# DSS_EDP0_V2A_CORE_VP_REGS_APB register map
Vendor: Texas Instruments
Registers are 32-bit, access per field, reset 0x0 unless marked. A register's access mark holds for its fields unless they carry their own. Offsets are as the file gives them; [hi:lo] are bit positions; {n}, {i} and the like mark numbered series; 'fields as' and 'values as' point back to an identical list.

## DSS_EDP0_V2A_CORE_VP_REGS_APB (part 2 of 3)
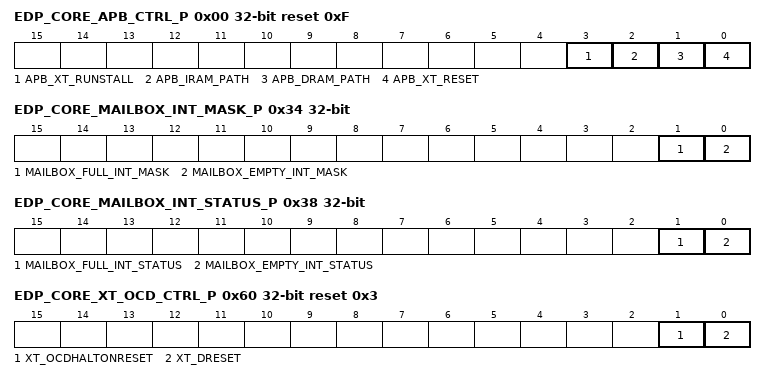
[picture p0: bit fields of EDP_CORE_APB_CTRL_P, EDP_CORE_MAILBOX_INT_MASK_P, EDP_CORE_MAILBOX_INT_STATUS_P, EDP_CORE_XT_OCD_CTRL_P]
0x00 EDP_CORE_APB_CTRL_P reset 0xF — APB main control register
  [3] APB_XT_RUNSTALL rw — When 1 stalls the CPU from executing further instructions.
  [2] APB_IRAM_PATH rw — Unused.
  [1] APB_DRAM_PATH rw — Unused.
  [0] APB_XT_RESET rw — Internal uCPU reset.
0x04 EDP_CORE_XT_INT_CTRL_P — Inernal CPU Interrupt Polarity Control Register.
  [1:0] XT_INT_POLARITY rw — Each bit inverts appropriate interrupt signal provided do internal CPU interrupt input.
0x08 EDP_CORE_MAILBOX_FULL_ADDR_P ro — Mailbox full indication status register. This register provides a status of the mailbox that is used to send messages from the Host processor to internal uCPU.Mailbox full flag can be a source of mailbox interrupt.
  [0] MAILBOX_FULL — Mailbox full indication.
0x0C EDP_CORE_MAILBOX_EMPTY_ADDR_P ro reset 0x1 — Mailbox empty indication status register. This register provides a status of the mailbox that is used to send responses from the internal uCPU to host processor as a result of previously sent message.Mailbox empty flag can be a source of not-empty mailbox interrupt.
  [0] MAILBOX_EMPTY — Mailbox empty indication.
0x10 EDP_CORE_MAILBOX0_WR_DATA_P — Mailbox write data register.
  [7:0] MAILBOX0_WR_DATA rw — Mailbox write data.
0x14 EDP_CORE_MAILBOX0_RD_DATA_P ro — Mailbox Read data register.
  [7:0] MAILBOX0_RD_DATA — Mailbox Read data.
0x18 EDP_CORE_KEEP_ALIVE_P ro — Software keep alive counter.
  [7:0] KEEP_ALIVE_CNT
0x1C EDP_CORE_VER_l_P ro — Software Version Register.
  [7:0] VER_LSB — Software Version lower byte.
0x20 EDP_CORE_VER_H_P ro — Software Version Register.
  [7:0] VER_MSB — Software Version higher byte.
0x24 EDP_CORE_VER_LIB_L_ADDR_P ro — Software Library Version Register.
  [7:0] SW_LIB_VER_L — Software Library Version lower byte.
0x28 EDP_CORE_VER_LIB_H_ADDR_P ro — Software Library Version Register.
  [7:0] SW_LIB_VER_H — Software Library Version higher byte.
0x2C EDP_CORE_SW_DEBUG_l_P ro — Software/Firmware Debug Register.
  [7:0] SW_DEBUG_7_0 — Register used for debug purposes [lower byte].
0x30 EDP_CORE_SW_DEBUG_H_P ro — Software/Firmware Debug Register.
  [7:0] SW_DEBUG_15_8 — Register used for debug purposes [higher byte].
0x34 EDP_CORE_MAILBOX_INT_MASK_P — Mailbox Interrupt mask register.
  [1] MAILBOX_FULL_INT_MASK rw — Mailbox Full Interrupt mask
  [0] MAILBOX_EMPTY_INT_MASK rw — Mailbox Not-empty Interrupt mask
0x38 EDP_CORE_MAILBOX_INT_STATUS_P ro — Mailbox Interrupt Status register.
  [1] MAILBOX_FULL_INT_STATUS — Mailbox full interrupt.
  [0] MAILBOX_EMPTY_INT_STATUS — Mailbox not-empty interrupt.
0x3C EDP_CORE_SW_CLK_l_P — Core Clock frequency
  [7:0] SW_CLOCK_VAL_L rw — Fractional of the clock decimal value.
0x40 EDP_CORE_SW_CLK_H_P reset 0x64 — Core Clock frequency
  [7:0] SW_CLOCK_VAL_H rw — Clock frequency in decimal values.
0x44 EDP_CORE_SW_EVENTS0_P ro — Bits [7:0] of the software events status vector. This register is used to report internal events that have been detected by the firmware to the host processor. Register is written by the internal uCPU. It is cleared upon read by the Host processor. Reported events can be source of interrupt reported in APB_INT_STATUS[1] register if this interrupt is enabled.Detailed description of the currently supported events can be found in HD Display TX Controller Programming Interface document.
  [7:0] SW_EVENTS7_0 — Each bit represents a separate event reported by the internal uCPU.
{0x44+4i} EDP_CORE_SW_EVENTS{i}_P ro (i=1..3) — SW Event {i} register
  [7:0] SW_EVENTS{8i+7}_{8i} — Each bit represents a separate event reported by the internal uCPU.
0x60 EDP_CORE_XT_OCD_CTRL_P reset 0x3 — Internal CPU - On Chip Debug (OCD) Ctrl Register
  [1] XT_OCDHALTONRESET rw — Internal CPU - Halt On Reget configuration register
  [0] XT_DRESET rw — Internal CPU - Dreset control register
0x64 EDP_CORE_XT_OCD_CTRL_RO_P ro — Internal CPU - OCD R0 mode configuration
  [0] XT_XOCDMODE — Internal CPU - OCD mode configuration
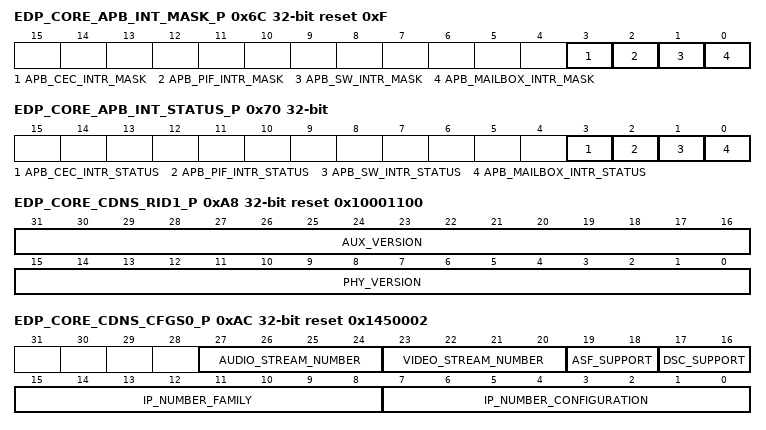
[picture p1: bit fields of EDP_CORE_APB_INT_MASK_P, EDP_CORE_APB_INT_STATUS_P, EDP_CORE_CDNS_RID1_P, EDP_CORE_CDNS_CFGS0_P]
0x6C EDP_CORE_APB_INT_MASK_P reset 0xF — APB Interrupt Mask Register
  [3] APB_CEC_INTR_MASK rw — Reserved field.
  [2] APB_PIF_INTR_MASK rw — PIF module Interrupt mask
  [1] APB_SW_INTR_MASK rw — SW Event Interrupt mask
  [0] APB_MAILBOX_INTR_MASK rw — Mailbox Interrupt mask
0x70 EDP_CORE_APB_INT_STATUS_P ro — APB interrupt status register
  [3] APB_CEC_INTR_STATUS — Reserved.
  [2] APB_PIF_INTR_STATUS — PIF module Interrupt status.
  [1] APB_SW_INTR_STATUS — SW Events Interrupt status.
  [0] APB_MAILBOX_INTR_STATUS — Mailbox Interrupt status.
0xA0 EDP_CORE_CDNS_DID_P ro reset 0x8546 — Number identifying the IP.Corresponds to IP Part Number.
  [31:0] IPVER — 0x8546 - DisplayPort 1.4/EmbeddedDisplayPort 1.4 Tx Combo Controller
0xA4 EDP_CORE_CDNS_RID0_P ro reset 0x2000 — Number identifying IP version.
  [15:0] IP_VERSION — IP version: r
0xA8 EDP_CORE_CDNS_RID1_P ro reset 0x10001100 — Numbers identifying PHY and AUX version
  [31:16] AUX_VERSION — AUX version: r
  [15:0] PHY_VERSION — PHY version: r
0xAC EDP_CORE_CDNS_CFGS0_P ro reset 0x1450002 — Numbers identifying the capabilities/configuration of the MHDP controller. Values not explicitely listed below ar ereserved for future use.
  [27:24] AUDIO_STREAM_NUMBER — Secondary configuration.
  [23:20] VIDEO_STREAM_NUMBER — Secondary configuration.
  [19:18] ASF_SUPPORT — Secondary configuration.
  [17:16] DSC_SUPPORT — Secondary configuration.
  [15:8] IP_NUMBER_FAMILY — Main configuration.
  [7:0] IP_NUMBER_CONFIGURATION — Main configuration.
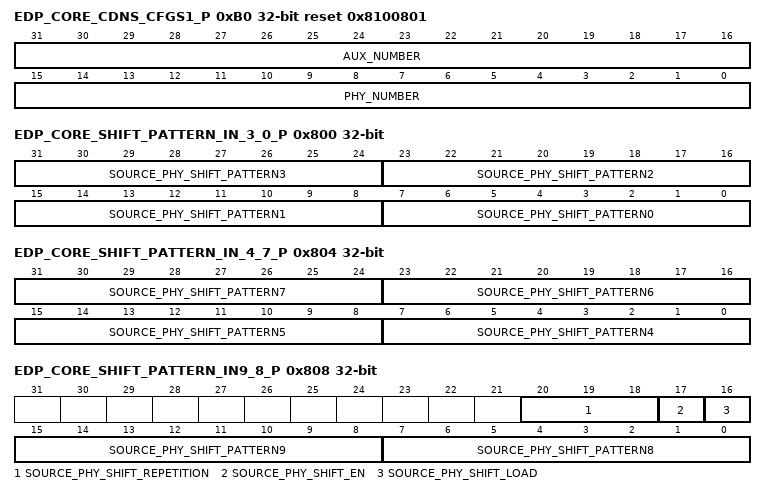
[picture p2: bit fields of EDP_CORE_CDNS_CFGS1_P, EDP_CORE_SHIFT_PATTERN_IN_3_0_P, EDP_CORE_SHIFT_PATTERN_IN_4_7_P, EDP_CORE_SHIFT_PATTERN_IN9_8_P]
0xB0 EDP_CORE_CDNS_CFGS1_P ro reset 0x8100801 — Numbers identifying type of PHY and AUX are integrated in the IPS. Fixed for a given IPS configuration.
  [31:16] AUX_NUMBER — AUX IP Number, according to versioning scheme.
  [15:0] PHY_NUMBER — PHY IP Number, according to versioning scheme.
0x800 EDP_CORE_SHIFT_PATTERN_IN_3_0_P rw — HDMI shift pattern 3-0
  [8n+7:8n] SOURCE_PHY_SHIFT_PATTERN{n} (n=0..3) — Input to hdmi_pattern_shift
0x804 EDP_CORE_SHIFT_PATTERN_IN_4_7_P rw — HDMI shift pattern 4-7
  [8n-25:8n-32] SOURCE_PHY_SHIFT_PATTERN{n} (n=4..7) — Input to hdmi_pattern_shift
0x808 EDP_CORE_SHIFT_PATTERN_IN9_8_P — HDMI shift pattern 9-8 with control bits
  [20:18] SOURCE_PHY_SHIFT_REPETITION rw — Shift repetition Number
  [17] SOURCE_PHY_SHIFT_EN rw — When 1 enable the Shift pattern Mechanism
  [16] SOURCE_PHY_SHIFT_LOAD rw — When 1 load the 80 bits of data
  [15:8] SOURCE_PHY_SHIFT_PATTERN9 rw — Input to hdmi_pattern_shift
  [7:0] SOURCE_PHY_SHIFT_PATTERN8 rw — Input to hdmi_pattern_shift
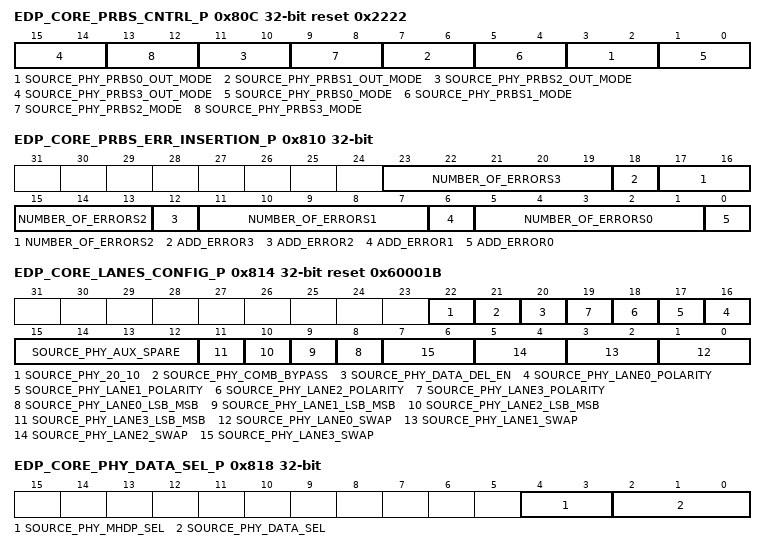
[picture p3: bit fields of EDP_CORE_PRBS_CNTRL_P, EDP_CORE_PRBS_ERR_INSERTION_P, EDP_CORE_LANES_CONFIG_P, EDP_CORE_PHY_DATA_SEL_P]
0x80C EDP_CORE_PRBS_CNTRL_P reset 0x2222 — PRBS control
  [4n+3:4n+2] SOURCE_PHY_PRBS{n}_OUT_MODE rw (n=0..3), [4n+1:4n] SOURCE_PHY_PRBS{n}_MODE rw (n=0..3)
0x810 EDP_CORE_PRBS_ERR_INSERTION_P — PRBS error insertion
  [6n+5:6n+1] NUMBER_OF_ERRORS{n} rw (n=0..3) — The number of errors to be inserted when add_error is high.
  [18] ADD_ERROR3 rw — When high the PRBS generator inserts the number of errors written in number_of_errors field.
  [12] ADD_ERROR2 rw — When high the PRBS generator inserts the number of errors written in number_of_errors field.
  [6] ADD_ERROR1 rw — When high the PRBS generator inserts the number of errors written in number_of_errors field
  [0] ADD_ERROR0 rw — When high the PRBS generator inserts the number of errors written in number_of_errors field
0x814 EDP_CORE_LANES_CONFIG_P reset 0x60001B — Lane control register: swap, order, polarity
  [22] SOURCE_PHY_20_10 rw — 1'b
  [21] SOURCE_PHY_COMB_BYPASS rw — Bypass swap invert and all combination
  [20] SOURCE_PHY_DATA_DEL_EN rw — enable configurable delay of lanes to be activated.if this bit is 0 the delay is only activated for DisplayPort mode with source_phy_data_sel=prbs or shift-mem
  [n+16] SOURCE_PHY_LANE{n}_POLARITY rw (n=0..3) — Reverse polarity of data, lane{n}
  [15:12] SOURCE_PHY_AUX_SPARE rw — Spare bits for aux **1.1**
  [n+8] SOURCE_PHY_LANE{n}_LSB_MSB rw (n=0..3) — Reverse order of data, lane{n}
  [2n+1:2n] SOURCE_PHY_LANE{n}_SWAP rw (n=0..3) — Swap control lane{n}
0x818 EDP_CORE_PHY_DATA_SEL_P — PHY data select DP/HDMI and HDMI data source
  [4:3] SOURCE_PHY_MHDP_SEL rw — 3'd
  [2:0] SOURCE_PHY_DATA_SEL rw — 3'd
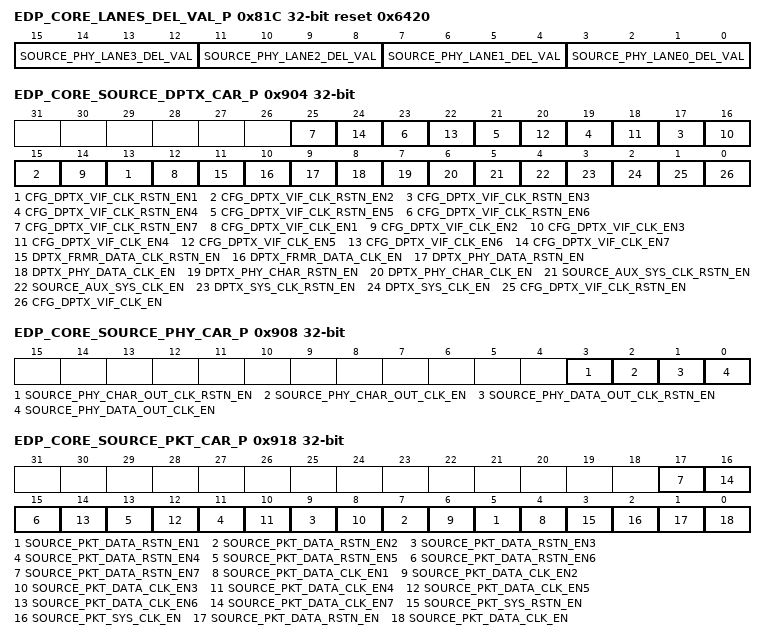
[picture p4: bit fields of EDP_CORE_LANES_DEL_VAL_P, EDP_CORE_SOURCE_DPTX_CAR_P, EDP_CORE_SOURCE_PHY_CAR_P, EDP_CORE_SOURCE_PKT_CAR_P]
0x81C EDP_CORE_LANES_DEL_VAL_P reset 0x6420 — Lane delay control
  [4n+3:4n] SOURCE_PHY_LANE{n}_DEL_VAL rw (n=0..3) — delay for lane {n}
0x904 EDP_CORE_SOURCE_DPTX_CAR_P — DP TX clock and reset ctrl register
  [2n+11] CFG_DPTX_VIF_CLK_RSTN_EN{n} rw (n=1..7) — dptx_vif_clk_rstn enable for stream number
  [2n+10] CFG_DPTX_VIF_CLK_EN{n} rw (n=1..7) — dptx_vif_clk enable for stream number
  [11] DPTX_FRMR_DATA_CLK_RSTN_EN rw — dptx_frmr_data_clk_rstn enable - active low
  [10] DPTX_FRMR_DATA_CLK_EN rw — dptx_frmr_data_clk enable - active high
  [9] DPTX_PHY_DATA_RSTN_EN rw — dptx_phy_data_rstn enable - active low
  [8] DPTX_PHY_DATA_CLK_EN rw — dptx_phy_data_clk enable - active high
  [7] DPTX_PHY_CHAR_RSTN_EN rw — dptx_phy_char_rstn enable - active low
  [6] DPTX_PHY_CHAR_CLK_EN rw — dptx_phy_char_clk enable - active high
  [5] SOURCE_AUX_SYS_CLK_RSTN_EN rw — source_aux_sys_clk_rstn enable - active low
  [4] SOURCE_AUX_SYS_CLK_EN rw — source_aux_sys_clk enable - active high
  [3] DPTX_SYS_CLK_RSTN_EN rw — dptx_sys_clk_rstn enable - active low
  [2] DPTX_SYS_CLK_EN rw — dptx_sys_clk enable - active high
  [1] CFG_DPTX_VIF_CLK_RSTN_EN rw — dptx_vif_clk_rstn enable - active low
  [0] CFG_DPTX_VIF_CLK_EN rw — dptx_vif_clk enable - active high
0x908 EDP_CORE_SOURCE_PHY_CAR_P — Source PHY clock and reset ctrl register
  [3] SOURCE_PHY_CHAR_OUT_CLK_RSTN_EN rw — source_phy_char_out_clk_rstn enable - active low
  [2] SOURCE_PHY_CHAR_OUT_CLK_EN rw — source_phy_char_out_clk enable - active high
  [1] SOURCE_PHY_DATA_OUT_CLK_RSTN_EN rw — source_phy_data_out_clk_rstn enable - active low
  [0] SOURCE_PHY_DATA_OUT_CLK_EN rw — source_phy_data_out_clk enable - active high
0x918 EDP_CORE_SOURCE_PKT_CAR_P — PKT clock and reset ctrl register
  [2n+3] SOURCE_PKT_DATA_RSTN_EN{n} rw (n=1..7) — source_pkt_data_rstn_en
  [2n+2] SOURCE_PKT_DATA_CLK_EN{n} rw (n=1..7) — source_pkt_data_clk_en
  [3] SOURCE_PKT_SYS_RSTN_EN rw — source_pkt_sys_rstn_en - active low
  [2] SOURCE_PKT_SYS_CLK_EN rw — source_pkt_sys_clk_en - active high
  [1] SOURCE_PKT_DATA_RSTN_EN rw — source_pkt_data_rstn_en - active low
  [0] SOURCE_PKT_DATA_CLK_EN rw — source_pkt_data_clk_en - active high
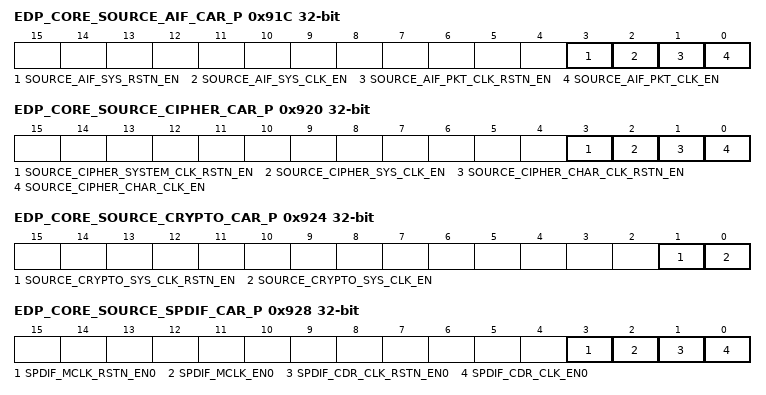
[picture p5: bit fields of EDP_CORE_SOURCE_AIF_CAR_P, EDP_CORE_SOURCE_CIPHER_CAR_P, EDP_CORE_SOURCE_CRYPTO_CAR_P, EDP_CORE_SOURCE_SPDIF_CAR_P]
0x91C EDP_CORE_SOURCE_AIF_CAR_P — AIF clock and reset ctrl register
  [3] SOURCE_AIF_SYS_RSTN_EN rw — source_aif_sys_rstn enable - active low
  [2] SOURCE_AIF_SYS_CLK_EN rw — source_aif_sys_clk enable - active high
  [1] SOURCE_AIF_PKT_CLK_RSTN_EN rw — source_aif_pkt_clk_rstn enable - active low
  [0] SOURCE_AIF_PKT_CLK_EN rw — source_aif_pkt_clk enable - active high
0x920 EDP_CORE_SOURCE_CIPHER_CAR_P — Cipher clock and reset ctrl register
  [3] SOURCE_CIPHER_SYSTEM_CLK_RSTN_EN rw — source_cipher_system_clk_rstn enable - active low [Only when HDCP used]
  [2] SOURCE_CIPHER_SYS_CLK_EN rw — source_cipher_sys_clk enable - active high [Only when HDCP used]
  [1] SOURCE_CIPHER_CHAR_CLK_RSTN_EN rw — source_cipher_char_clk_rstn enable - active low [Only when HDCP used]
  [0] SOURCE_CIPHER_CHAR_CLK_EN rw — source_cipher_char_clk enable - active high [Only when HDCP used]
0x924 EDP_CORE_SOURCE_CRYPTO_CAR_P — Crypto clock and reset ctrl register
  [1] SOURCE_CRYPTO_SYS_CLK_RSTN_EN rw — source_crypto_sys_clk_rstn enable - active low [Only when HDCP used]
  [0] SOURCE_CRYPTO_SYS_CLK_EN rw — source_crypto_sys_clk enable - active high [Only when HDCP used]
0x928 EDP_CORE_SOURCE_SPDIF_CAR_P — SPDIF clock and reset ctrl register
  [3] SPDIF_MCLK_RSTN_EN0 rw — spdif_mclk_rstn enable
  [2] SPDIF_MCLK_EN0 rw — spdif_mclk enable
  [1] SPDIF_CDR_CLK_RSTN_EN0 rw — spdif_cdr_clk_rstn enable
  [0] SPDIF_CDR_CLK_EN0 rw — spdif_cdr_clk enable
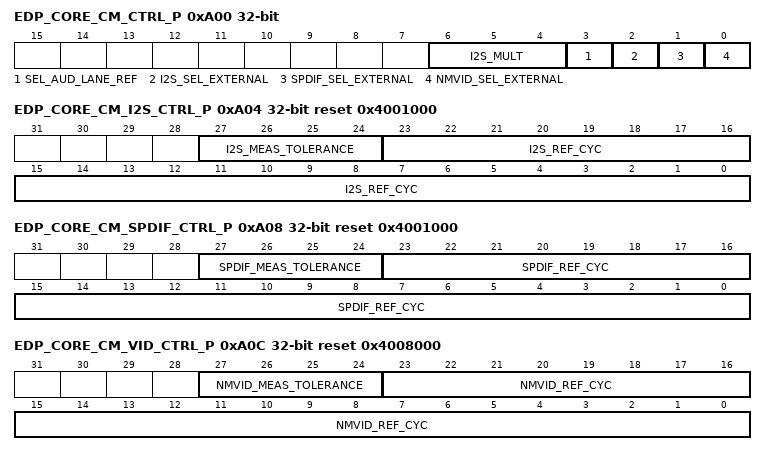
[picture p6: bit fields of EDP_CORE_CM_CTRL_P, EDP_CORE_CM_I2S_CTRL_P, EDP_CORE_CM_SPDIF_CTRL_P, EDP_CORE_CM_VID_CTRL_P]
0xA00 EDP_CORE_CM_CTRL_P — Clock Meter control
  [6:4] I2S_MULT rw — Select the division of N value for different I2S TDM configuration
  [3] SEL_AUD_LANE_REF rw — When 1 Select Audio CLK as a reference [HDMI]
  [2] I2S_SEL_EXTERNAL rw — When 1 Select external values of NMAUD [N/A] for I2S
  [1] SPDIF_SEL_EXTERNAL rw — When 1 Select external values of NMAUD [N/A] for SPDIF
  [0] NMVID_SEL_EXTERNAL rw — When 1 Select external values of NMVID [N/A]
0xA04 EDP_CORE_CM_I2S_CTRL_P reset 0x4001000 — I2S clock control
  [27:24] I2S_MEAS_TOLERANCE rw — Measurement tolerance of Audio clock to be stable in clocks
  [23:0] I2S_REF_CYC rw — Reference cycles for I2S Audio meter
0xA08 EDP_CORE_CM_SPDIF_CTRL_P reset 0x4001000 — SPDIF clock control
  [27:24] SPDIF_MEAS_TOLERANCE rw — SPDIF measurement tolerance to be stable in clocks
  [23:0] SPDIF_REF_CYC rw — Reference cycles of SPDIF measurement
0xA0C EDP_CORE_CM_VID_CTRL_P reset 0x4008000 — Video clock control
  [27:24] NMVID_MEAS_TOLERANCE rw — Video measurement tolerance in pixel clock cycles
  [23:0] NMVID_REF_CYC rw — Video Reference cycles
0xA10 EDP_CORE_CM_LANE_CTRL_P — Lane control
  [23:0] LANE_REF_CYC rw — Reference cycles when using lane clock as Reference [DP]
0xA14 EDP_CORE_I2S_NM_STABLE_P ro — I2S clock stable, audio clock measured
  [0] I2S_MNAUD_STABLE — I2S NMAUD Mesurment stable
0xA18 EDP_CORE_I2S_NCTS_STABLE_P ro — I2S clock stable, lane clock measured
  [0] I2S_NCTS_STABLE — i2s CTS measurement stable
0xA1C EDP_CORE_SPDIF_NM_STABLE_P ro — SPDIF clock stable, audio clock measured
  [0] SPDIF_MNAUD_STABLE — SPDIF NMAUD measurement stable
0xA20 EDP_CORE_SPDIF_NCTS_STABLE_P ro — SPDIF clock stable, lane clock measured
  [0] SPDIF_NCTS_STABLE — SPDIF CTS measurement stable
0xA24 EDP_CORE_NMVID_MEAS_STABLE_P ro — Video clock stable
  [0] ST_NMVID_MEAS_STABLE — Pixel clock NMVID measurement stable
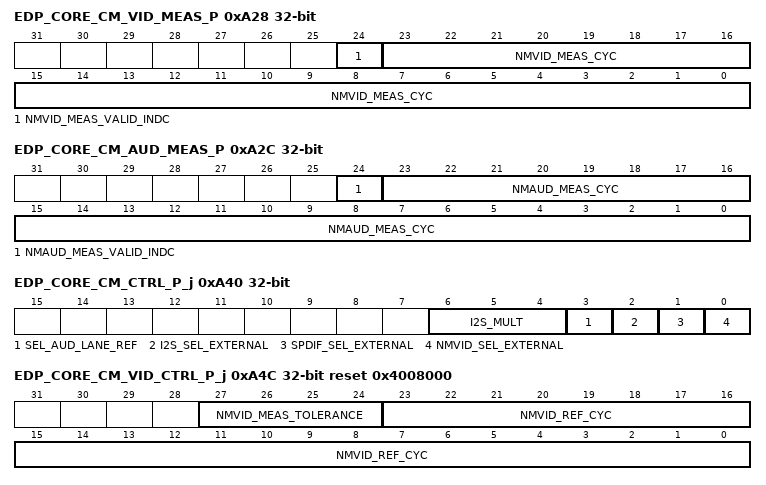
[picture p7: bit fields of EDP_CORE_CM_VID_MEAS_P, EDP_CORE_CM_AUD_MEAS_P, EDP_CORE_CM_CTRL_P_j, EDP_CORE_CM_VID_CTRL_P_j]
0xA28 EDP_CORE_CM_VID_MEAS_P — Video cycles measure
  [24] NMVID_MEAS_VALID_INDC rw — When Toggle Valid pulse is generated to sample MNVID fix value
  [23:0] NMVID_MEAS_CYC rw — Fixed Value for NVID , The MVID is nmvid_ref_cyc
0xA2C EDP_CORE_CM_AUD_MEAS_P — Audio cycles measure
  [24] NMAUD_MEAS_VALID_INDC rw — When Toggle Valid pulse is generated to sample MNAUD fix value
  [23:0] NMAUD_MEAS_CYC rw — Fixed Value for NAUD, The MAUD is lane_ref_cyc
0xA30 EDP_CORE_I2S_MEAS_P ro — I2S clock measurement HDMI
  [23:0] I2_MEAS — I2S measurement value
0xA34 EDP_CORE_SPDIF_MEAS_P ro — SPDIF clock measurement HDMI
  [23:0] SPDIF_MEAS — SPDIF Clock Meter measurement value [in DP]
0xA38 EDP_CORE_NMVID_MEAS_P ro — Video clock measurement
  [23:0] NMVID_MEAS — Video clock measurement value
0xA40 EDP_CORE_CM_CTRL_P_j — Clock Meter control Offset = A40h + (j * 40h); where j = 0h to 2h
  fields as EDP_CORE_CM_CTRL_P
0xA4C EDP_CORE_CM_VID_CTRL_P_j reset 0x4008000 — Video clock control Offset = A4Ch + (j * 40h); where j = 0h to 2h
  fields as EDP_CORE_CM_VID_CTRL_P
0xA64 EDP_CORE_NMVID_MEAS_STABLE_P_J ro — Video clock stable Offset = A64h + (j * 40h); where j = 0h to 2h
  [0] ST_NMVID_MEAS_STABLE — Pixel clock NMVID measurement stable
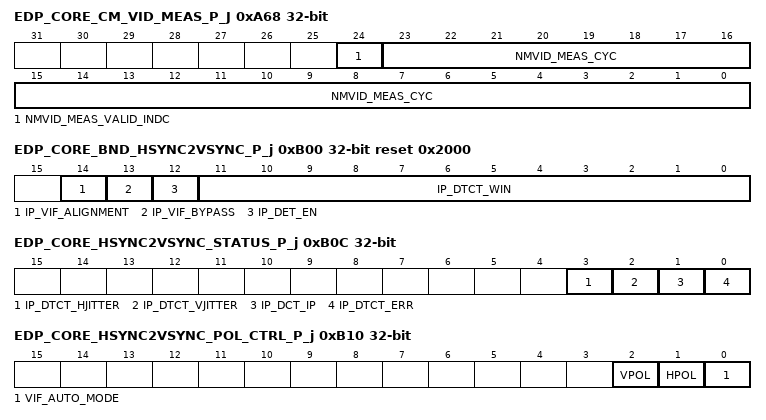
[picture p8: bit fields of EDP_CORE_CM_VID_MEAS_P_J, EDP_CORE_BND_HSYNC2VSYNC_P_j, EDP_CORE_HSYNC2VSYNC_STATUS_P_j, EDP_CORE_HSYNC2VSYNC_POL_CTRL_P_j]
0xA68 EDP_CORE_CM_VID_MEAS_P_J — Video cycles measure Offset = A68h + (j * 40h); where j = 0h to 2h
  fields as EDP_CORE_CM_VID_MEAS_P
0xA78 EDP_CORE_NMVID_MEAS_P_J ro — Video clock measurement Offset = A78h + (j * 40h); where j = 0h to 2h
  [23:0] NMVID_MEAS — Video clock measurement value
0xB00 EDP_CORE_BND_HSYNC2VSYNC_P_j reset 0x2000 — Video Input Interface Setting Register Offset = B00h + (j * 20h); where j = 0h to 3h
  [14] IP_VIF_ALIGNMENT rw — Alignment of the input pixel data at the pixel interface:
  [13] IP_VIF_BYPASS rw — Bypass video interface.
  [12] IP_DET_EN rw — Enable detection of Interlace formats after decided if the polarity is Automatic or Manual detection.
  [11:0] IP_DTCT_WIN rw — Bound for HSYNC to VSYNC for all fields.
0xB04 EDP_CORE_HSYNC2VSYNC_F1_L1_P_J ro — Status of HSYNC to VSYNC Distance Counter 1. Offset = B04h + (j * 20h); where j = 0h to 3h
  [15:0] IP_DTCT_HSYNC2VSYNC_F1 — Value of HSYNC to VSYNC field 1.
0xB08 EDP_CORE_HSYNC2VSYNC_F2_L1_P_J ro — Status of HSYNC to VSYNC Distance Counter 2 Offset = B08h + (j * 20h); where j = 0h to 3h
  [15:0] IP_DTCT_HSYNC2VSYNC_F2 — Value of HSYNC to VSYNC field 2.
0xB0C EDP_CORE_HSYNC2VSYNC_STATUS_P_j ro — Video Interface Status Register Offset = B0Ch + (j * 20h); where j = 0h to 3h
  [3] IP_DTCT_HJITTER — Asserted when jitter is observed on htotal i.e.
  [2] IP_DTCT_VJITTER — Asserted when jitter is observed on vtotal i.e.
  [1] IP_DCT_IP — When asserted interlaced format is detected else progressive format.
  [0] IP_DTCT_ERR — Asserted when HSYNC to VSYNC bound is violated.
0xB10 EDP_CORE_HSYNC2VSYNC_POL_CTRL_P_j — Setting Polarity of HSYNC and VSYNC Offset = B10h + (j * 20h); where j = 0h to 3h
  [2] VPOL rw — VSYNC polarity:
  [1] HPOL rw — HSYNC polarity:
  [0] VIF_AUTO_MODE rw — Automatic or Manual configuration of the polarity:
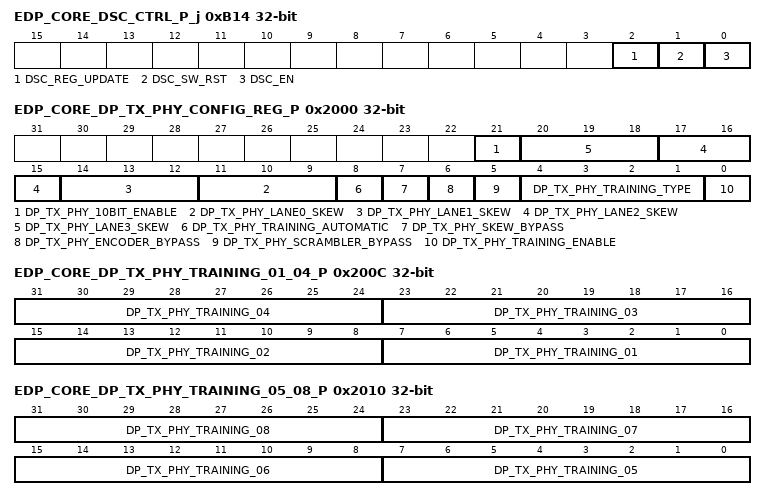
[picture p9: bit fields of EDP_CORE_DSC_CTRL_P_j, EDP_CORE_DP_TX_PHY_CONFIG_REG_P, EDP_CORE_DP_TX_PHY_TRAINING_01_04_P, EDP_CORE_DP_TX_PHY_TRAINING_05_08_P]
0xB14 EDP_CORE_DSC_CTRL_P_j — DSC Setting Register Offset = B14h + (j * 20h); where j = 0h to 3h
  [2] DSC_REG_UPDATE rw — DSC registers update: active HIGH.
  [1] DSC_SW_RST rw — DSC software reset: active HIGH.
  [0] DSC_EN rw — DSC enable bit:
0x2000 EDP_CORE_DP_TX_PHY_CONFIG_REG_P — DPTX PHY control
  [21] DP_TX_PHY_10BIT_ENABLE rw — Used to enable the
  [3n+11:3n+9] DP_TX_PHY_LANE{n}_SKEW rw (n=0..3) — Specifies the programmable lane{n} skew.
  [8] DP_TX_PHY_TRAINING_AUTOMATIC rw — When set, the dp_tx_phy_scrambler_bypass and the dp_tx_phy_encoder_bypass bits are ignored during training pattern generation.
  [7] DP_TX_PHY_SKEW_BYPASS rw — Used to bypass the lane skew.
  [6] DP_TX_PHY_ENCODER_BYPASS rw — Used to bypass the encoder.
  [5] DP_TX_PHY_SCRAMBLER_BYPASS rw — Used to bypass the scrambler.
  [4:1] DP_TX_PHY_TRAINING_TYPE rw — Specifies the training pattern type used as follows:
  [0] DP_TX_PHY_TRAINING_ENABLE rw — Enables the training sequence [when set to 1].
0x2004 EDP_CORE_DP_TX_PHY_SW_RESET_P — DPTC PHY software reset
  [0] DP_TX_PHY_SW_RST rw — Software reset.
0x2008 EDP_CORE_DP_TX_PHY_SCRAMBLER_SEED_P reset 0xFFFF — Scrambler seed
  [15:0] DP_TX_PHY_SCRAMBLER_SEED rw — Scrambler seed range
0x200C EDP_CORE_DP_TX_PHY_TRAINING_01_04_P rw — Custom training value bytes 1-4
  [8n-1:8n-8] DP_TX_PHY_TRAINING_{n:02} (n=1..4) — Byte {n} of the
0x2010 EDP_CORE_DP_TX_PHY_TRAINING_05_08_P rw — Custom training value bytes 5-8
  [8n-33:8n-40] DP_TX_PHY_TRAINING_{n:02} (n=5..8) — Byte {n} of the
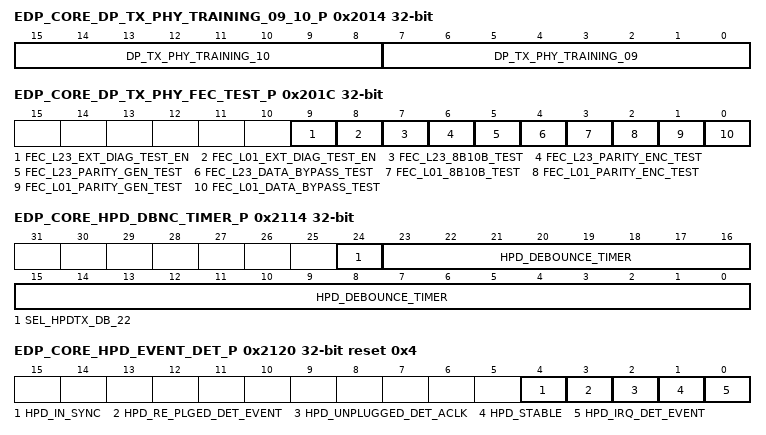
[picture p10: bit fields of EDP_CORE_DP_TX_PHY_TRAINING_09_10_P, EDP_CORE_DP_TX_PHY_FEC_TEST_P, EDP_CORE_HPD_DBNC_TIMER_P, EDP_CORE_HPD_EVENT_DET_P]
0x2014 EDP_CORE_DP_TX_PHY_TRAINING_09_10_P — Custom training value bytes 9-10
  [15:8] DP_TX_PHY_TRAINING_10 rw — Byte 10 of the
  [7:0] DP_TX_PHY_TRAINING_09 rw — Byte 9 of the
0x2018 EDP_CORE_DP_TX_PHY_SR_INTERVAL_P reset 0xFC — Custom CP2520 SR interval
  [15:0] DP_TX_PHY_SR_INTERVAL rw — CP2520 test pattern SR Interval definition
0x201C EDP_CORE_DP_TX_PHY_FEC_TEST_P — FEC IP test register. Used for fault injection into the FEC IP to test diagnostic mechanisms.
  [9] FEC_L23_EXT_DIAG_TEST_EN rw — Encoder 1 external diagnostic test enable.
  [8] FEC_L01_EXT_DIAG_TEST_EN rw — Encoder 0 external diagnostic test enable.
  [7] FEC_L23_8B10B_TEST rw — When asserted, a corruption is injected at the interface of the internal diagnostic module which generate a fault in the 8b10b check of the FEC IP datapath for lanes 2 and 3.
  [6] FEC_L23_PARITY_ENC_TEST rw — When asserted, a corruption is injected at the interface of the internal diagnostic module which generate a fault in the parity enc check of the FEC IP datapath for lanes 2 and 3.
  [5] FEC_L23_PARITY_GEN_TEST rw — When asserted, a corruption is injected at the interface of the internal diagnostic module which generate a fault in the parity gen check of the FEC IP datapaths for lanes 2 and 3.
  [4] FEC_L23_DATA_BYPASS_TEST rw — When asserted, a corruption is injected at the interface of the internal diagnostic module which generate a fault in the bypass check for of the FEC IP datapathe for lanes 2 and 3.
  [3] FEC_L01_8B10B_TEST rw — When asserted, a corruption is injected at the interface of the internal diagnostic module which generate a fault in the 8b10b check of the FEC IP datapath for lanes 0 and 1.
  [2] FEC_L01_PARITY_ENC_TEST rw — When asserted, a corruption is injected at the interface of the internal diagnostic module which generate a fault in the parity enc check of the FEC IP datapath for lanes 0 and 1.
  [1] FEC_L01_PARITY_GEN_TEST rw — When asserted, a corruption is injected at the interface of the internal diagnostic module which generate a fault in the parity gen check of the FEC IP datapath for lanes 0 and 1.
  [0] FEC_L01_DATA_BYPASS_TEST rw — When asserted, a corruption is injected at the interface of the internal diagnostic module which generate a fault in the bypass check for of the FEC IP datapath for lanes 0 and 1.
0x2100 EDP_CORE_HPD_IRQ_DET_MIN_TIMER_P reset 0xC350 — HPD min timer for irq, define the minimum pclk cycles that the HPD pulse will be considered as IRQ
  [23:0] HPD_IRQ_DET_MIN_TIMER rw — HPD min timer for interrupt.
0x2104 EDP_CORE_HPD_IRQ_DET_MAX_TIMER_P reset 0x186A0 — HPD max timer for irq, define the maximum pclk cycles that the HPD pulse will be considered as IRQ
  [23:0] HPD_IRQ_DET_MAX_TIMER rw — HPD max timer
0x2108 EDP_CORE_HPD_UNPLGED_DET_MIN_TIMER_P reset 0x30D40 — HPD min timer for HPD detect, define the minimum pclk cycles that the HPD is low
  [23:0] HPD_UNPLGED_DET_MIN_TIMER rw — HPD unplugged timer
0x210C EDP_CORE_HPD_STABLE_TIMER_P reset 0x186A0 — Timer for detecting HPD stable, count in system clock cycles.
  [23:0] HPD_STABLE_TIMER rw — HPD stable timer counter setup.
0x2110 EDP_CORE_HPD_FILTER_TIMER_P reset 0x7A12 — Timer for filtering small pulses on HPD input.
  [23:0] HPD_FILTER_TIMER rw — HPD glitch filter counter setup.
0x2114 EDP_CORE_HPD_DBNC_TIMER_P — HPD debouncer control
  [24] SEL_HPDTX_DB_22 rw — Debouncer enable
  [23:0] HPD_DEBOUNCE_TIMER rw — HPD debounce timer setup.
0x211C EDP_CORE_HPD_EVENT_MASK_P — Mask of HPD interrupt and status
  [3:0] HPD_EVENTS_MASK rw — HPD mask events
0x2120 EDP_CORE_HPD_EVENT_DET_P ro reset 0x4 — HPD interrupt and status
  [4] HPD_IN_SYNC — HDP in sync detected
  [3] HPD_RE_PLGED_DET_EVENT — HPD Re-Plugged event detected.
  [2] HPD_UNPLUGGED_DET_ACLK — HPD Un-Plugged event detected.
  [1] HPD_STABLE — HPD Stable indication
  [0] HPD_IRQ_DET_EVENT — Bit
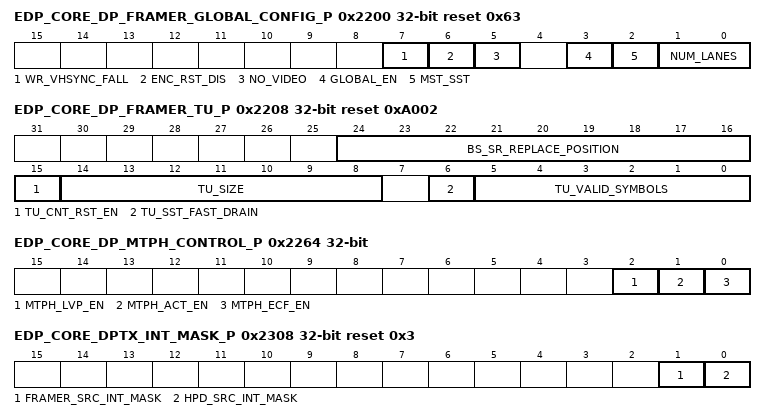
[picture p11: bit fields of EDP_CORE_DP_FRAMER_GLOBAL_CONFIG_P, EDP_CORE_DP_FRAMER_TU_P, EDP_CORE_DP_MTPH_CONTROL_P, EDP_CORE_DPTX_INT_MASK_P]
0x2200 EDP_CORE_DP_FRAMER_GLOBAL_CONFIG_P reset 0x63 — Global configuration of the framer module.
  [7] WR_VHSYNC_FALL rw — When set to 1 change the write state machine to sync on falling edge of vsync.
  [6] ENC_RST_DIS rw — Unused.
  [5] NO_VIDEO rw — No-video mode configuration bit.
  [3] GLOBAL_EN rw — Global enable for complete Framer module, active high.
  [2] MST_SST rw — Mode select:
  [1:0] NUM_LANES rw — Number of lanes:
0x2204 EDP_CORE_DP_SW_RESET_P — Unused. Bit [0] kept RW for software backward compatibility.
  [0] SW_RST rw — Unused.
0x2208 EDP_CORE_DP_FRAMER_TU_P reset 0xA002 — Transfer Unit configuration register. Relevant only in SST mode. These register must be set before transitioning to video mode.
  [24:16] BS_SR_REPLACE_POSITION rw — Static debug register.
  [15] TU_CNT_RST_EN rw — Unused.
  [14:8] TU_SIZE rw — Transfer Unit size.
  [6] TU_SST_FAST_DRAIN rw — Allow the video FIFO to drain faster at end of line.
  [5:0] TU_VALID_SYMBOLS rw — Number of valid symbols per Transfer Unit [TU].
0x2218 EDP_CORE_DP_FRAMER_BS_SR_INTRVL_P reset 0x200 — SR insertion interval for SST mode.
  [9:0] BS_SR_INTERVAL rw — Static debug register.
0x2258 EDP_CORE_DP_MTPH_ECF_SLOTS_31_0_P rw — Bits [31:1] contains which MST timeslot 31-1 should be encrypted.Bit [0] must be set to 1 to enable encryption.Relevant only in MST mode.
  [31:0] TSLOT_ENCRYPT31_0
0x225C EDP_CORE_DP_MTPH_ECF_SLOTS_63_32_P rw — Contains which MST timeslot 63-32 should be encrypted. This register must be set properly before ECF sequence is triggered. Relevant only in MST mode.
  [31:0] TSLOT_ENCRYPT63_32
0x2260 EDP_CORE_DP_MTPH_LVP_SYMBOL_P reset 0x531F — Link Verification Pattern value to be inserted in the MTP header. Relevant only in MST mode.
  [15:0] MTPH_LVP_SYM rw — Symbol value for LINK VERIFICATION PATTERN [LVP]
0x2264 EDP_CORE_DP_MTPH_CONTROL_P — MTP header control. Relevant only in MST mode.
  [2] MTPH_LVP_EN rw — Unused.
  [1] MTPH_ACT_EN wo — MST feature when written with value 1, an ACT sequence will be triggered for slot allocation control.
  [0] MTPH_ECF_EN rw — Unused.
0x226C EDP_CORE_DP_MTPH_STATUS_P ro — MTP header status. Relevant only in MST mode.
  [0] MTPH_ACT_STATUS — Status of ACT insertion.
0x2300 EDP_CORE_DPTX_LANE_EN_P — DPTX lane enable
  [3:0] DPTX_LANE_ENABLE rw — DPTX lane enable each lane as a bit when 1 lane is enabled
0x2304 EDP_CORE_DPTX_ENHNCD_P — DPTX enhanced mode control register. Relevant only in SST mode. In MST mode it is ignored.
  [0] DPTX_ENHANCED_MODE rw — Enhanced mode control
0x2308 EDP_CORE_DPTX_INT_MASK_P reset 0x3 — DPTX Interrupt mask.
  [1] FRAMER_SRC_INT_MASK rw — Framer mask interrupt
  [0] HPD_SRC_INT_MASK rw — HPD mask interrupt
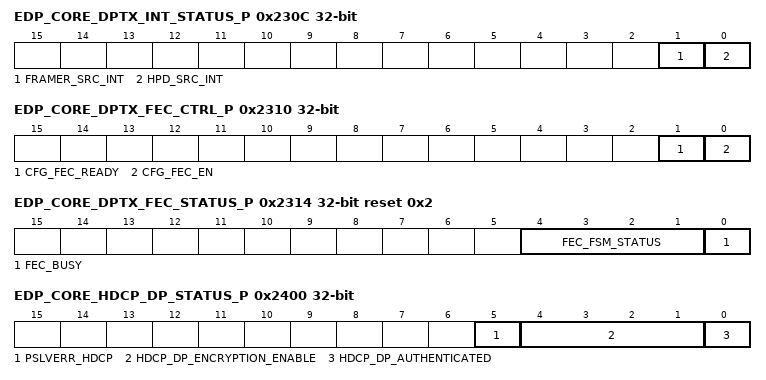
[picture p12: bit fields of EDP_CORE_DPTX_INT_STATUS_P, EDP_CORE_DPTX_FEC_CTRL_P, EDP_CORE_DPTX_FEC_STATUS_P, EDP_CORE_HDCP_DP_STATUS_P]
0x230C EDP_CORE_DPTX_INT_STATUS_P ro — DPTX interrupt status register. This interrupts are tracked by firmware and not accessible directly to the Host processor.
  [1] FRAMER_SRC_INT — Framer interrupt - not used.
  [0] HPD_SRC_INT — HPD interrupt.
0x2310 EDP_CORE_DPTX_FEC_CTRL_P — DPTX FEC control register.
  [1] CFG_FEC_READY rw — Equivalent DPCD register FEC_READY, enable alternative CP coding.
  [0] CFG_FEC_EN rw — FEC Enable
0x2314 EDP_CORE_DPTX_FEC_STATUS_P ro reset 0x2 — FEC status register.
  [4:1] FEC_FSM_STATUS
  [0] FEC_BUSY — FEC Active status.
0x2400 EDP_CORE_HDCP_DP_STATUS_P ro — HDCP DP status register.
  [5] PSLVERR_HDCP — APB slave error status from HDCP module has been reported when this bit is set to 1.
  [4:1] HDCP_DP_ENCRYPTION_ENABLE — Encryption is enabled when this bit is set to 1.
  [0] HDCP_DP_AUTHENTICATED — HDCP 1.3 authentication is enabled when this bit is set to 1.
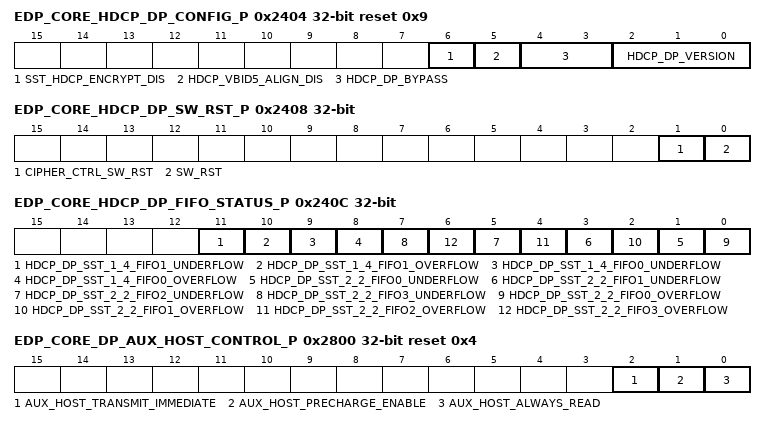
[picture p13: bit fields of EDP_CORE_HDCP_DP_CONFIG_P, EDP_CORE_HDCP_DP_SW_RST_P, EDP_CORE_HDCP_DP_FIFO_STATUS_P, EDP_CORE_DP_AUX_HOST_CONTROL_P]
0x2404 EDP_CORE_HDCP_DP_CONFIG_P reset 0x9 — HDCP DP config register.
  [6] SST_HDCP_ENCRYPT_DIS rw — Disable automatic HDCP encryption in SST mode when cipher is authenticated.
  [5] HDCP_VBID5_ALIGN_DIS rw — Debug register, no longer used.
  [4:3] HDCP_DP_BYPASS rw
  [2:0] HDCP_DP_VERSION rw — HDCP version.
0x2408 EDP_CORE_HDCP_DP_SW_RST_P — HDCP DP software reset register
  [1] CIPHER_CTRL_SW_RST rw — Software reset of cipher control logic only.
  [0] SW_RST rw — Software reset.
0x240C EDP_CORE_HDCP_DP_FIFO_STATUS_P ro — HDCP DP FIFO status register.
  [11] HDCP_DP_SST_1_4_FIFO1_UNDERFLOW — SST HDCP1.4 fifo1 underflow.
  [10] HDCP_DP_SST_1_4_FIFO1_OVERFLOW — SST HDCP1.4 fifo1 overflow.
  [9] HDCP_DP_SST_1_4_FIFO0_UNDERFLOW — SST HDCP1.4 fifo0 underflow.
  [8] HDCP_DP_SST_1_4_FIFO0_OVERFLOW — SST HDCP1.4 fifo0 overflow.
  [2n+1] HDCP_DP_SST_2_2_FIFO{n}_UNDERFLOW (n=0..3) — SST HDCP2.2 fifo{n} underflow.
  [2n] HDCP_DP_SST_2_2_FIFO{n}_OVERFLOW (n=0..3) — SST HDCP2.2 fifo{n} overflow.
0x2800 EDP_CORE_DP_AUX_HOST_CONTROL_P reset 0x4 — DP AUX control register.
  [2] AUX_HOST_TRANSMIT_IMMEDIATE rw — This bit is used only in DP_OUT mode.
  [1] AUX_HOST_PRECHARGE_ENABLE rw — According to the current standard the tx precharge is done by sending 10 to 16 data_0 on the line before the SYNC.
  [0] AUX_HOST_ALWAYS_READ rw — Normally, the aux_rx is disabled during transmit.
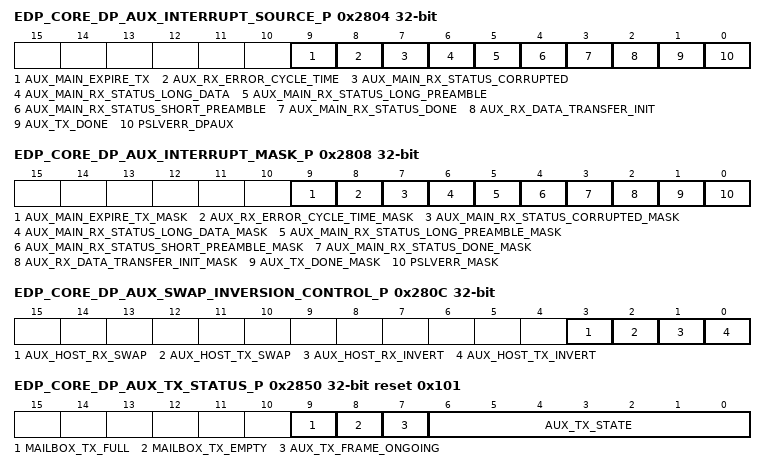
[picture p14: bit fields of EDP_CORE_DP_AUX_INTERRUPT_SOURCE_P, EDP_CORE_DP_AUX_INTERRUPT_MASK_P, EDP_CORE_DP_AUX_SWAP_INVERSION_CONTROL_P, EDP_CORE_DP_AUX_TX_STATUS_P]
0x2804 EDP_CORE_DP_AUX_INTERRUPT_SOURCE_P ro — Status of the DP_AUX interrupt sources. These interrupts are tracked by firmware and not accessible directly to the Host processor.
  [9] AUX_MAIN_EXPIRE_TX — Timer expire [external] in DP_OUT.
  [8] AUX_RX_ERROR_CYCLE_TIME — Cycle time error.
  [7] AUX_MAIN_RX_STATUS_CORRUPTED — The received transaction corrupted during the data phase [bad STOP, or unaligned STOP].
  [6] AUX_MAIN_RX_STATUS_LONG_DATA — The received transaction had more than 20 data bytes.
  [5] AUX_MAIN_RX_STATUS_LONG_PREAMBLE — The received transaction had preamble greater than the preamble_max.
  [4] AUX_MAIN_RX_STATUS_SHORT_PREAMBLE — The received transaction had preamble shorter than the preamble_max.
  [3] AUX_MAIN_RX_STATUS_DONE — This module control the packet extraction and packet read from the memory.
  [2] AUX_RX_DATA_TRANSFER_INIT — Rx data transfer may be initiated.
  [1] AUX_TX_DONE — Tx data transfer finished.
  [0] PSLVERR_DPAUX — APB slave error interrupt from DP AUX module.
0x2808 EDP_CORE_DP_AUX_INTERRUPT_MASK_P — Mask vector of the DP_AUX interrupt sources.
  [9] AUX_MAIN_EXPIRE_TX_MASK rw — aux_main_expire_external mask
  [8] AUX_RX_ERROR_CYCLE_TIME_MASK rw
  [7] AUX_MAIN_RX_STATUS_CORRUPTED_MASK rw
  [6] AUX_MAIN_RX_STATUS_LONG_DATA_MASK rw
  [5] AUX_MAIN_RX_STATUS_LONG_PREAMBLE_MASK rw
  [4] AUX_MAIN_RX_STATUS_SHORT_PREAMBLE_MASK rw
  [3] AUX_MAIN_RX_STATUS_DONE_MASK rw
  [2] AUX_RX_DATA_TRANSFER_INIT_MASK rw — rx_data_transfer_init mask
  [1] AUX_TX_DONE_MASK rw
  [0] PSLVERR_MASK rw — Mask for pslverr_dpaux interrupt.
0x280C EDP_CORE_DP_AUX_SWAP_INVERSION_CONTROL_P — Ordering and inversion of transmit/receive on Auxiliary Channel.
  [3] AUX_HOST_RX_SWAP rw — Shift right [LSB first] of the income data
  [2] AUX_HOST_TX_SWAP rw — Shift right the output data [LSB first]
  [1] AUX_HOST_RX_INVERT rw — Invert rx input and output data to AUXILIARY CHANNEL
  [0] AUX_HOST_TX_INVERT rw — Invert tx input and output data to AUXILIARY CHANNEL
0x2810 EDP_CORE_DP_AUX_SEND_NACK_TRANSACTION_P — NACK transaction send
  [0] AUX_HOST_SEND_NACK_TRANSACTION rw — Send nack transaction by AUX_TX.
0x2814 EDP_CORE_DP_AUX_CLEAR_RX_P — RX bits clear.
  [0] AUX_HOST_CLEAR_RX rw — Clear all rx bits in register 64,65.This command is an indication that the processing of last receive transaction was completed and the AUX_RX can start looking for new receive transaction.
0x2818 EDP_CORE_DP_AUX_CLEAR_TX_P — TX bits clear.
  [0] AUX_HOST_CLEAR_TX rw — Clear all external bits in registers 64,67.This command used in DP_IN mode.
0x281C EDP_CORE_DP_AUX_TIMER_STOP_P — Stop timer operation.
  [0] AUX_HOST_STOP_TIMER rw
0x2820 EDP_CORE_DP_AUX_TIMER_CLEAR_P — Clear timer operation.
  [0] AUX_HOST_CLEAR_TIMER rw — Stop timer operation.
0x2824 EDP_CORE_DP_AUX_RESET_SW_P — Soft reset of the DP_AUX.
  [0] AUX_HOST_SW_RESET rw — Reset all DP_AUX state machines and clear all the status bits.
0x2828 EDP_CORE_DP_AUX_DIVIDE_2M_P reset 0xB — SYS_CLK and 2 MHz clock ratio. This register is used to ensure correct AUX channel bitrate for different values of a system clock.
  [7:0] AUX_HOST_DIVIDE_2M rw — The ratio between sys_clk and 2MHz, [[sys_clk frequency/2MHz] - 1], for 25MHz sys_clk the value is 11.
0x282C EDP_CORE_DP_AUX_TX_PREACHARGE_LENGTH_P reset 0x10 — Pre charge field length.
  [5:0] AUX_HOST_PRECHARGE_LENGTH rw — Length of pre charge field, standard definition is 10 to 16 bits/clocks.
0x2830 EDP_CORE_DP_AUX_FREQUENCY_1M_MAX_P reset 0x22 — Maximum legal receiving frequency.
  [10:0] AUX_HOST_1M_MAX rw — The maximum legal frequency receiving from the line by the standard is 1.25MHz.The calculation is:[1.25 MHz cycle time]/[sys_clk[-15%] cycle time] 800/
0x2834 EDP_CORE_DP_AUX_FREQUENCY_1M_MIN_P reset 0x9 — Minimum legal receiving frequency.
  [10:0] AUX_HOST_1M_MIN rw — The minimum legal frequency receiving from the line by the standard is 0.83MHz.The calculation is:[0.83 MHz cycle time]/[sys_clk[+15%] cycle time] 1200/
0x2838 EDP_CORE_DP_AUX_RX_PRE_MIN_P reset 0x1A — Minimum received preamble length
  [5:0] AUX_HOST_PRE_MIN rw — Valid minimum length of preamble during receive.
0x283C EDP_CORE_DP_AUX_RX_PRE_MAX_P reset 0x20 — Maximum received preamble length.
  [5:0] AUX_HOST_PRE_MAX rw — Valid maximum length of preamble during receive.
0x2840 EDP_CORE_DP_AUX_TIMER_PRESET_P reset 0x1D4C — DP_AUX_MAIN start value
  [15:0] AUX_HOST_TIMER_PRESET rw — The preset value of the timer in DP_IN mode.
0x2844 EDP_CORE_DP_AUX_NACK_FORMAT_P reset 0x20 — Transmit pattern.
  [7:0] AUX_HOST_NACK_FORMAT rw — Nack or defer pattern for transmit [ 00100000 for defer, 00010000 for nack]
0x2848 EDP_CORE_DP_AUX_TX_DATA_P — AUX Mailbox write data.
  [9:0] MAILBOX_TX_DATA rw — TX data byte written to the mailbox.
0x284C EDP_CORE_DP_AUX_RX_DATA_P ro — AUX Mailbox read data.
  [9:0] MAILBOX_RX_DATA — Read data from the mailbox.
0x2850 EDP_CORE_DP_AUX_TX_STATUS_P ro reset 0x101 — AUX_TX status.
  [9] MAILBOX_TX_FULL — AUX Mailbox TX full flag.
  [8] MAILBOX_TX_EMPTY — AUX Mailbox TX empty flag.
  [7] AUX_TX_FRAME_ONGOING — Frame transmission status.
  [6:0] AUX_TX_STATE — Aux_tx state machine register.
0x2854 EDP_CORE_DP_AUX_RX_STATUS_P ro reset 0x1010141 — AUX_RX status
  [31:24] AUX_RX_DATA_STATE — AUX_RX SM state.
  [23] AUX_MAIN_RX_STATUS_LAST_EQUAL — The receive transaction is equal to the previous transaction.
  [19:16] AUX_RX_HHLL_STATE — AUX_RX hhll state machine register.
  [13:8] AUX_RX_PREAMBLE_STATE — AUX_RX preamble state machine register.
  [7] MAILBOX_RX_FULL — AUX Mailbox RX full flag.
  [6] MAILBOX_RX_EMPTY — AUX Mailbox RX empty flag.
  [5] AUX_RX_FRAME_ONGOING — Frame reception status.
  [4:0] AUX_RX_MAIN_STATE — AUX_RX main state machine register.
0x2858 EDP_CORE_DP_AUX_RX_CYCLE_COUNTER_P ro — AUX RX counter status.
  [10:0] AUX_RX_CYCLE_COUNTER — Count system clocks from last change in the auxiliary line input.
0x285C EDP_CORE_DP_AUX_MAIN_STATES_P ro — DP_AUX MAIN State Machines status. Used only for debug purpose.
  [13:10] AUX_MAIN_EXTERNAL_STATE — AUX_MAIN external state machine register.
  [9:8] AUX_MAIN_TIMER_STATE — AUX_MAIN timer state machine.
  [6:5] AUX_MAIN_DP_STATE — AUX_MAIN dp state machine.
  [4:2] AUX_MAIN_RX_STATE — AUX_MAIN rx state machine.
  [1:0] AUX_MAIN_TX_STATE — AUX_MAIN tx state machine.
0x2860 EDP_CORE_DP_AUX_MAIN_TIMER_P ro — DP_AUX MAIN timer status.
  [15:0] AUX_MAIN_TIMER
0x2864 EDP_CORE_DP_AUX_AFE_OUT_P — Test mode configuration.
  [3] AUX_HOST_AUX_AFE_PRECH rw — Drive the aux_data_prech output to the AFE when aux_host_afe_if_test_en [bit 0 ] is set.
  [2] AUX_HOST_AUX_AFE_DATA rw — Drive the aux_data_out output to the AFE when aux_host_afe_if_test_en [bit 0 ] is set.
  [1] AUX_HOST_AUX_AFE_CLK rw — Drive the aux_clk_out output to the AFE when aux_host_afe_if_test_en [bit 0 ] is set.
  [0] AUX_HOST_AFE_IF_TEST_EN rw — TESTER mode enable.
0x3000 EDP_CORE_MSA_HORIZONTAL_0_P_j rw — MSA horizontal parameters. This settings define MSA content (not used for input video stream parameters). This field must be set prior video is enabled and must not be changed when video transmission is active. Offset = 3000h + (j * 80h); where j = 0h to 3h
  [31:16] PCK_STUFF_HSTART — MSA Hstart value.
  [15:0] PCK_STUFF_HTOTAL — MSA HTotal value.
0x3004 EDP_CORE_MSA_HORIZONTAL_1_P_j rw — MSA horizontal parameters. This settings define MSA content (not used for input video stream parameters). This field must be set prior video is enabled and must not be changed when video transmission is active. Offset = 3004h + (j * 80h); where j = 0h to 3h
  [31:16] PCK_STUFF_HWIDTH — MSA Hwidth parameter.
  [15] PCK_STUFF_HSYNCPOLARITY — MSA HSync Polarity.
  [14:0] PCK_STUFF_HSYNCWIDTH — MSA HSyncWidth parameter.
0x3008 EDP_CORE_MSA_VERTICAL_0_P_j rw — MSA vertical parameters. This settings define MSA content (not used for input video stream parameters). This field must be set prior video is enabled and must not be changed when video transmission is active. Offset = 3008h + (j * 80h); where j = 0h to 3h
  [31:16] PCK_STUFF_VSTART — MSA Vstart parameter.
  [15:0] PCK_STUFF_VTOTAL — MSA Vtotal parameter.
0x300C EDP_CORE_MSA_VERTICAL_1_P_j rw — MSA vertical parameters. This settings define MSA content (not used for input video stream parameters). This field must be set prior video is enabled and must not be changed when video transmission is active. Offset = 300Ch + (j * 80h); where j = 0h to 3h
  [31:16] PCK_STUFF_VHEIGHT — MSA VHeigh parameter.
  [15] PCK_STUFF_VSYNCPOLARITY — MSA VSyncPolarity.
  [14:0] PCK_STUFF_VSYNCWIDTH — MSA VSyncWidth parameter.
0x3010 EDP_CORE_MSA_MISC_P_J reset 0x20000 — MSA MISC0 and MISC1 control register. This field must be set prior video is enabled and must not be changed when video transmission is active. Offset = 3010h + (j * 80h); where j = 0h to 3h
  [17] MSA_IN_MID_INTERLACE_EN rw — MSA transmission control in interlaced mode.
  [16] MSA_MISC1_INV rw — L/R toggle for interlaced and field sequential video.
  [15:8] MSA_MISC1 rw — MAS Miscellaneous1 as described in DisplayPort specification.
  [7:0] MSA_MISC0 rw — MSA Miscellaneous0 as described in DisplayPort specification.
